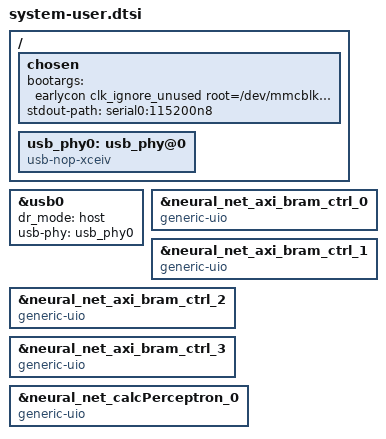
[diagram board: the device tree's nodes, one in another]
/include/ "system-conf.dtsi"
/ {
    chosen {
        bootargs = "earlycon clk_ignore_unused  root=/dev/mmcblk0p2 rw rootwait  uio_pdrv_genirq.of_id=generic-uio";
        stdout-path = "serial0:115200n8";
    };

	usb_phy0: usb_phy@0 {
		compatible = "usb-nop-xceiv";
		#phy-cells = <0>;
	};
};

&usb0 {
	dr_mode = "host";
	usb-phy = <&usb_phy0>;
};

&neural_net_axi_bram_ctrl_0 {
    compatible = "generic-uio";
};

&neural_net_axi_bram_ctrl_1 {
    compatible = "generic-uio";
};

&neural_net_axi_bram_ctrl_2 {
    compatible = "generic-uio";
};

&neural_net_axi_bram_ctrl_3 {
    compatible = "generic-uio";
};

&neural_net_calcPerceptron_0 {
    compatible = "generic-uio";
};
